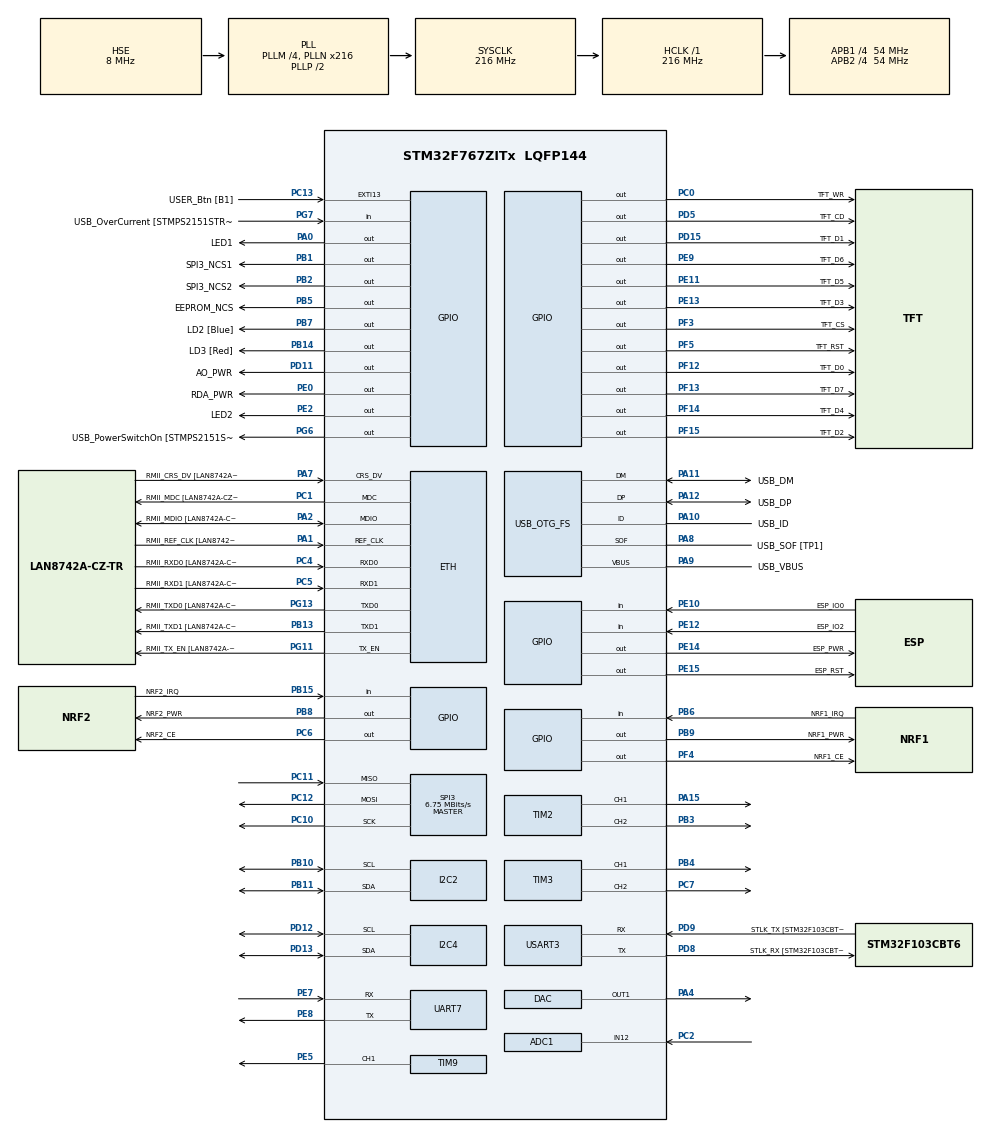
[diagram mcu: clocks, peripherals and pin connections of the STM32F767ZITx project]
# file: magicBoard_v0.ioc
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ADC1.Channel-0\#ChannelRegularConversion=ADC_CHANNEL_12
ADC1.Channel-1\#ChannelRegularConversion=ADC_CHANNEL_TEMPSENSOR
ADC1.DMAContinuousRequests=ENABLE
ADC1.ExternalTrigConv=ADC_EXTERNALTRIGCONV_T4_TRGO
ADC1.NbrOfConversion=2
ADC1.NbrOfConversionFlag=1
ADC1.Rank-0\#ChannelRegularConversion=1
ADC1.Rank-1\#ChannelRegularConversion=2
ADC1.SamplingTime-0\#ChannelRegularConversion=ADC_SAMPLETIME_480CYCLES
ADC1.SamplingTime-1\#ChannelRegularConversion=ADC_SAMPLETIME_480CYCLES
ADC1.master=1
Dma.ADC1.1.Direction=DMA_PERIPH_TO_MEMORY
Dma.ADC1.1.FIFOMode=DMA_FIFOMODE_DISABLE
Dma.ADC1.1.Instance=DMA2_Stream0
Dma.ADC1.1.MemDataAlignment=DMA_MDATAALIGN_WORD
Dma.ADC1.1.MemInc=DMA_MINC_ENABLE
Dma.ADC1.1.Mode=DMA_CIRCULAR
Dma.ADC1.1.PeriphDataAlignment=DMA_PDATAALIGN_WORD
Dma.ADC1.1.PeriphInc=DMA_PINC_DISABLE
Dma.ADC1.1.Priority=DMA_PRIORITY_LOW
Dma.Request0=UART7_RX
Dma.Request1=ADC1
Dma.Request2=USART3_RX
Dma.UART7_RX.0.Direction=DMA_PERIPH_TO_MEMORY
Dma.UART7_RX.0.FIFOMode=DMA_FIFOMODE_DISABLE
Dma.UART7_RX.0.Instance=DMA1_Stream3
Dma.UART7_RX.0.MemDataAlignment=DMA_MDATAALIGN_BYTE
Dma.UART7_RX.0.MemInc=DMA_MINC_ENABLE
Dma.UART7_RX.0.Mode=DMA_CIRCULAR
Dma.UART7_RX.0.PeriphDataAlignment=DMA_PDATAALIGN_BYTE
Dma.UART7_RX.0.PeriphInc=DMA_PINC_DISABLE
Dma.UART7_RX.0.Priority=DMA_PRIORITY_LOW
Dma.USART3_RX.2.Direction=DMA_PERIPH_TO_MEMORY
Dma.USART3_RX.2.FIFOMode=DMA_FIFOMODE_DISABLE
Dma.USART3_RX.2.Instance=DMA1_Stream1
Dma.USART3_RX.2.MemDataAlignment=DMA_MDATAALIGN_BYTE
Dma.USART3_RX.2.MemInc=DMA_MINC_ENABLE
Dma.USART3_RX.2.Mode=DMA_CIRCULAR
Dma.USART3_RX.2.PeriphDataAlignment=DMA_PDATAALIGN_BYTE
Dma.USART3_RX.2.PeriphInc=DMA_PINC_DISABLE
Dma.USART3_RX.2.Priority=DMA_PRIORITY_LOW
ETH.MediaInterface=HAL_ETH_RMII_MODE
FREERTOS.Queues01=wirelessData,16,uint16_t,0,Dynamic,NULL,NULL;wifiData,16,uint16_t,0,Dynamic,NULL,NULL
FREERTOS.Tasks01=defaultTask,24,128,StartDefaultTask,Default,NULL,Dynamic,NULL,NULL;nrfCOM,40,512,Start_nrfCOM,Default,NULL,Dynamic,NULL,NULL;displayTask,8,512,Start_displayTask,Default,NULL,Dynamic,NULL,NULL;uartCLI,8,128,Start_uartCLI,Default,NULL,Dynamic,NULL,NULL;WIFITask,24,128,StartWIFITask,Default,NULL,Dynamic,NULL,NULL
FREERTOS.configUSE_NEWLIB_REENTRANT=1
I2C2.Timing=0x20404768
I2C4.Timing=0x20404768
Mcu.Family=STM32F7
Mcu.Name=STM32F767ZITx
Mcu.Package=LQFP144
NVIC.DMA1_Stream1_IRQn=true\:5\:0\:false\:false\:true\:true\:false\:true\:true
NVIC.DMA1_Stream3_IRQn=true\:5\:0\:false\:false\:true\:true\:false\:true\:true
NVIC.DMA2_Stream0_IRQn=true\:5\:0\:false\:false\:true\:true\:false\:true\:true
NVIC.PriorityGroup=NVIC_PRIORITYGROUP_4
NVIC.RCC_IRQn=true\:5\:0\:false\:false\:true\:true\:true\:false\:true
NVIC.TIM8_TRG_COM_TIM14_IRQn=true\:15\:0\:false\:false\:true\:false\:false\:true\:true
NVIC.TimeBase=TIM8_TRG_COM_TIM14_IRQn
NVIC.TimeBaseIP=TIM14
NVIC.UART7_IRQn=true\:5\:0\:false\:false\:true\:true\:true\:true\:true
PA0/WKUP.GPIO_Label=LED1
PA0/WKUP.Signal=GPIO_Output
PA1.GPIO_Label=RMII_REF_CLK [LAN8742A-CZ-TR_REFCLK0]
PA1.Mode=RMII
PA1.Signal=ETH_REF_CLK
PA10.GPIO_Label=USB_ID
PA10.Mode=OTG/Dual_Role_Device
PA10.Signal=USB_OTG_FS_ID
PA11.GPIO_Label=USB_DM
PA11.Mode=OTG/Dual_Role_Device
PA11.Signal=USB_OTG_FS_DM
PA12.GPIO_Label=USB_DP
PA12.Mode=OTG/Dual_Role_Device
PA12.Signal=USB_OTG_FS_DP
PA13.GPIO_Label=TMS
PA13.Mode=Serial_Wire
PA13.Signal=SYS_JTMS-SWDIO
PA14.GPIO_Label=TCK
PA14.Mode=Serial_Wire
PA14.Signal=SYS_JTCK-SWCLK
PA15.Signal=S_TIM2_CH1_ETR
PA2.GPIO_Label=RMII_MDIO [LAN8742A-CZ-TR_MDIO]
PA2.Mode=RMII
PA2.Signal=ETH_MDIO
PA4.Signal=COMP_DAC1_group
PA7.GPIO_Label=RMII_CRS_DV [LAN8742A-CZ-TR_CRS_DV]
PA7.Mode=RMII
PA7.Signal=ETH_CRS_DV
PA8.GPIO_Label=USB_SOF [TP1]
PA8.Mode=Activate_SOF_FS
PA8.Signal=USB_OTG_FS_SOF
PA9.GPIO_Label=USB_VBUS
PA9.Mode=Activate_VBUS
PA9.Signal=USB_OTG_FS_VBUS
PB1.GPIO_Label=SPI3_NCS1
PB1.GPIO_Speed=GPIO_SPEED_FREQ_LOW
PB1.PinState=GPIO_PIN_SET
PB1.Signal=GPIO_Output
PB10.Mode=I2C
PB10.Signal=I2C2_SCL
PB11.Mode=I2C
PB11.Signal=I2C2_SDA
PB13.GPIO_Label=RMII_TXD1 [LAN8742A-CZ-TR_TXD1]
PB13.Mode=RMII
PB13.Signal=ETH_TXD1
PB14.GPIO_Label=LD3 [Red]
PB14.Signal=GPIO_Output
PB15.GPIO_Label=NRF2_IRQ
PB15.Signal=GPIO_Input
PB2.GPIO_Label=SPI3_NCS2
PB2.PinState=GPIO_PIN_SET
PB2.Signal=GPIO_Output
PB3.Signal=S_TIM2_CH2
PB4.Signal=S_TIM3_CH1
PB5.GPIO_Label=EEPROM_NCS
PB5.PinState=GPIO_PIN_SET
PB5.Signal=GPIO_Output
PB6.GPIO_Label=NRF1_IRQ
PB6.Signal=GPIO_Input
PB7.GPIO_Label=LD2 [Blue]
PB7.Signal=GPIO_Output
PB8.GPIO_Label=NRF2_PWR
PB8.PinState=GPIO_PIN_SET
PB8.Signal=GPIO_Output
PB9.GPIO_Label=NRF1_PWR
PB9.PinState=GPIO_PIN_SET
PB9.Signal=GPIO_Output
PC0.GPIO_Label=TFT_WR
PC0.Signal=GPIO_Output
PC1.GPIO_Label=RMII_MDC [LAN8742A-CZ-TR_MDC]
PC1.Mode=RMII
PC1.Signal=ETH_MDC
PC10.Mode=Full_Duplex_Master
PC10.Signal=SPI3_SCK
PC11.Mode=Full_Duplex_Master
PC11.Signal=SPI3_MISO
PC12.Mode=Full_Duplex_Master
PC12.Signal=SPI3_MOSI
PC13.GPIO_Label=USER_Btn [B1]
PC13.Signal=GPXTI13
PC14/OSC32_IN.Mode=LSE-External-Oscillator
PC14/OSC32_IN.Signal=RCC_OSC32_IN
PC15/OSC32_OUT.Mode=LSE-External-Oscillator
PC15/OSC32_OUT.Signal=RCC_OSC32_OUT
PC2.Signal=ADCx_IN12
PC4.GPIO_Label=RMII_RXD0 [LAN8742A-CZ-TR_RXD0]
PC4.Mode=RMII
PC4.Signal=ETH_RXD0
PC5.GPIO_Label=RMII_RXD1 [LAN8742A-CZ-TR_RXD1]
PC5.Mode=RMII
PC5.Signal=ETH_RXD1
PC6.GPIO_Label=NRF2_CE
PC6.Signal=GPIO_Output
PC7.Signal=S_TIM3_CH2
PD11.GPIO_Label=AO_PWR
PD11.PinState=GPIO_PIN_RESET
PD11.Signal=GPIO_Output
PD12.Mode=I2C
PD12.Signal=I2C4_SCL
PD13.Mode=I2C
PD13.Signal=I2C4_SDA
PD15.GPIO_Label=TFT_D1
PD15.Signal=GPIO_Output
PD5.GPIO_Label=TFT_CD
PD5.Signal=GPIO_Output
PD8.GPIO_Label=STLK_RX [STM32F103CBT6_PA3]
PD8.Mode=Asynchronous
PD8.Signal=USART3_TX
PD9.GPIO_Label=STLK_TX [STM32F103CBT6_PA2]
PD9.Mode=Asynchronous
PD9.Signal=USART3_RX
PE0.GPIO_Label=RDA_PWR
PE0.Signal=GPIO_Output
PE10.GPIO_Label=ESP_IO0
PE10.GPIO_PuPd=GPIO_NOPULL
PE10.Signal=GPIO_Input
PE11.GPIO_Label=TFT_D5
PE11.Signal=GPIO_Output
PE12.GPIO_Label=ESP_IO2
PE12.GPIO_PuPd=GPIO_NOPULL
PE12.Signal=GPIO_Input
PE13.GPIO_Label=TFT_D3
PE13.Signal=GPIO_Output
PE14.GPIO_Label=ESP_PWR
PE14.PinState=GPIO_PIN_SET
PE14.Signal=GPIO_Output
PE15.GPIO_Label=ESP_RST
PE15.Signal=GPIO_Output
PE2.GPIO_Label=LED2
PE2.Signal=GPIO_Output
PE5.Signal=S_TIM9_CH1
PE7.Mode=Asynchronous
PE7.Signal=UART7_RX
PE8.Mode=Asynchronous
PE8.Signal=UART7_TX
PE9.GPIO_Label=TFT_D6
PE9.Signal=GPIO_Output
PF12.GPIO_Label=TFT_D0
PF12.Signal=GPIO_Output
PF13.GPIO_Label=TFT_D7
PF13.Signal=GPIO_Output
PF14.GPIO_Label=TFT_D4
PF14.Signal=GPIO_Output
PF15.GPIO_Label=TFT_D2
PF15.Signal=GPIO_Output
PF3.GPIO_Label=TFT_CS
PF3.Signal=GPIO_Output
PF4.GPIO_Label=NRF1_CE
PF4.Signal=GPIO_Output
PF5.GPIO_Label=TFT_RST
PF5.Signal=GPIO_Output
PG11.GPIO_Label=RMII_TX_EN [LAN8742A-CZ-TR_TXEN]
PG11.Mode=RMII
PG11.Signal=ETH_TX_EN
PG13.GPIO_Label=RMII_TXD0 [LAN8742A-CZ-TR_TXD0]
PG13.Mode=RMII
PG13.Signal=ETH_TXD0
PG6.GPIO_Label=USB_PowerSwitchOn [STMPS2151STR_EN]
PG6.Signal=GPIO_Output
PG7.GPIO_Label=USB_OverCurrent [STMPS2151STR_FAULT]
PG7.Signal=GPIO_Input
PH0/OSC_IN.GPIO_Label=MCO [STM32F103CBT6_PA8]
PH0/OSC_IN.Mode=HSE-External-Clock-Source
PH0/OSC_IN.Signal=RCC_OSC_IN
PH1/OSC_OUT.Mode=HSE-External-Clock-Source
PH1/OSC_OUT.Signal=RCC_OSC_OUT
ProjectManager.HeapSize=0x200
ProjectManager.StackSize=0x400
ProjectManager.TargetToolchain=STM32CubeIDE
RCC.48MHZClocksFreq_Value=24000000
RCC.AHBFreq_Value=216000000
RCC.APB1CLKDivider=RCC_HCLK_DIV4
RCC.APB1Freq_Value=54000000
RCC.APB1TimFreq_Value=216000000
RCC.APB2CLKDivider=RCC_HCLK_DIV4
RCC.APB2Freq_Value=54000000
RCC.APB2TimFreq_Value=216000000
RCC.CortexFreq_Value=216000000
RCC.HCLKFreq_Value=216000000
RCC.HSE_VALUE=8000000
RCC.HSI_VALUE=16000000
RCC.PLLM=4
RCC.PLLMUL=RCC_PLL_MUL9
RCC.PLLN=216
RCC.PLLQ=9
RCC.PRESCALERUSB=RCC_USBCLKSOURCE_PLL_DIV1_5
RCC.RCC_TIM_PRescaler_Selection=RCC_TIMPRES_ACTIVATED
RCC.RTCClockSelection=RCC_RTCCLKSOURCE_LSE
RCC.SYSCLKFreq_VALUE=216000000
RCC.SYSCLKSource=RCC_SYSCLKSOURCE_PLLCLK
RCC.SYSCLKSourceVirtual=RCC_SYSCLKSOURCE_PLLCLK
RCC.USBFreq_Value=48000000
RCC.VCOOutputFreq_Value=432000000
SH.ADCx_IN12.0=ADC1_IN12,IN12
SH.COMP_DAC1_group.0=DAC_OUT1,DAC_OUT1
SH.S_TIM2_CH1_ETR.0=TIM2_CH1,PWM Generation1 CH1
SH.S_TIM2_CH2.0=TIM2_CH2,PWM Generation2 CH2
SH.S_TIM3_CH1.0=TIM3_CH1,PWM Generation1 CH1
SH.S_TIM3_CH2.0=TIM3_CH2,PWM Generation2 CH2
SH.S_TIM9_CH1.0=TIM9_CH1,PWM Generation1 CH1
SPI3.BaudRatePrescaler=SPI_BAUDRATEPRESCALER_8
SPI3.CalculateBaudRate=6.75 MBits/s
SPI3.DataSize=SPI_DATASIZE_8BIT
SPI3.Direction=SPI_DIRECTION_2LINES
SPI3.Mode=SPI_MODE_MASTER
SPI3.VirtualType=VM_MASTER
TIM2.Channel-PWM\ Generation1\ CH1=TIM_CHANNEL_1
TIM2.Channel-PWM\ Generation2\ CH2=TIM_CHANNEL_2
TIM3.Channel-PWM\ Generation1\ CH1=TIM_CHANNEL_1
TIM3.Channel-PWM\ Generation2\ CH2=TIM_CHANNEL_2
TIM4.Channel-Output\ Compare1\ No\ Output=TIM_CHANNEL_1
TIM4.Period=9999
TIM4.Prescaler=1080
TIM4.TIM_MasterOutputTrigger=TIM_TRGO_UPDATE
TIM9.Channel-PWM\ Generation1\ CH1=TIM_CHANNEL_1
USART3.VirtualMode-Asynchronous=VM_ASYNC
VP_ADC1_TempSens_Input.Mode=IN-TempSens
VP_FREERTOS_VS_CMSIS_V2.Mode=CMSIS_V2
VP_RTC_VS_RTC_Activate.Mode=RTC_Enabled
VP_RTC_VS_RTC_Calendar.Mode=RTC_Calendar
VP_SYS_VS_tim14.Mode=TIM14
VP_TIM2_VS_ClockSourceINT.Mode=Internal
VP_TIM3_VS_ClockSourceINT.Mode=Internal
VP_TIM4_VS_ClockSourceINT.Mode=Internal
VP_TIM4_VS_no_output1.Mode=Output Compare1 No Output
VP_TIM9_VS_ClockSourceINT.Mode=Internal
board=NUCLEO-F767ZI

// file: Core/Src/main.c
/* USER CODE BEGIN Header */
/**
  ******************************************************************************
  * @file           : main.c
  * @brief          : Main program body
  ******************************************************************************
  * @attention
  *
  * Copyright (c) 2022 STMicroelectronics.
  * All rights reserved.
  *
  * This software is licensed under terms that can be found in the LICENSE file
  * in the root directory of this software component.
  * If no LICENSE file comes with this software, it is provided AS-IS.
  *
  ******************************************************************************
  */
/* USER CODE END Header */
#include "main.h"
#include "cmsis_os.h"
#include "adc.h"
#include "dac.h"
#include "dma.h"
#include "eth.h"
#include "i2c.h"
#include "rtc.h"
#include "spi.h"
#include "tim.h"
#include "usart.h"
#include "usb_otg.h"
#include "gpio.h"

/* USER CODE BEGIN Includes */
#include <stdio.h>

#include "nrf24l01p_driver.h"
#include "nrf24l01p_driver_B.h"

#include "esp8266_http_server.h"

#include "nvm_app.h"

#include "rda5807m.h"

#include "tft.h"
#include "fonts.h"
#include "functions.h"

#include "cli.h"

#include "cmd_dispatcher.h"

#include "print_magneto.h"
#include "calibri16.h"
/* USER CODE END Includes */

/* USER CODE BEGIN PD */
#define WIFI_DEMO 0
#define TFT_DEMO 0
#define NRF_DEMO 0
#define EEPROM_DEMO 1
#define FM_RADIO_DEMO 0
#define INT_ADC_DEMO 0
#define DEMO_ENDLESS_LOOP 0
/* USER CODE END PD */

void SystemClock_Config(void);
void PeriphCommonClock_Config(void);
void MX_FREERTOS_Init(void);

int main(void)
{
  /* USER CODE BEGIN 1 */

	/* User input structure*/
	cli_t cli = {0};
#if TFT_DEMO
  uint32_t tft_Cursor = 5;
  uint32_t tft_Line = 300;
  char tft_TestStr[]= "I am a demo application for the magiBoard!";
  RTC_TimeTypeDef tft_Time = {0};
#endif

#if NRF_DEMO
  uint8_t nrf_lng1 = 0;
  uint8_t nrf_lng2 = 0;
  uint8_t nrf1_tx[33] = {0};
  uint8_t nrf1_rx[33] = {0};
  uint8_t nrf2_tx[33] = {0};
  uint8_t nrf2_rx[33] = {0};
#endif
  /* USER CODE END 1 */

  /* MCU Configuration--------------------------------------------------------*/

  /* Reset of all peripherals, Initializes the Flash interface and the Systick. */
  HAL_Init();

  /* Configure the system clock */
  SystemClock_Config();

/* Configure the peripherals common clocks */
  PeriphCommonClock_Config();

  /* Initialize all configured peripherals */
  MX_GPIO_Init();
  MX_DMA_Init();
  MX_USART3_UART_Init();
  MX_USB_OTG_FS_USB_Init();
  MX_DAC_Init();
  MX_SPI3_Init();
  MX_TIM3_Init();
  MX_ETH_Init();
  MX_UART7_Init();
  MX_TIM2_Init();
  MX_I2C2_Init();
  MX_I2C4_Init();
  MX_ADC1_Init();
  MX_TIM9_Init();
  MX_RTC_Init();
  MX_TIM4_Init();
  /* USER CODE BEGIN 2 */

  /* Initiliaze UART-console input */
  cli_init();

  /* Initiliaze LCD */
  reset();
  tft_init(readID());
  fillScreen(BLACK);
  HAL_GPIO_WritePin(LED1_GPIO_Port, LED1_Pin, GPIO_PIN_SET);

#if INT_ADC_DEMO
  //measurements_open();
#endif
#if TFT_DEMO
  /* TFT functionality overview*/

  reset();
  tft_init(readID());
  fillScreen(BLACK);

  /* Print a size-16 string - general usage*/
  for(uint32_t i = 0; i < strlen(tft_TestStr); i++)
  {
	  tft_Cursor += sPrintCalibri16(tft_Cursor, tft_Line, tft_TestStr[i] - ASCII_OFFSET, WHITE);
  }

  /* Get time */
  HAL_RTC_GetTime(&hrtc, &tft_Time, RTC_FORMAT_BIN);

  /* Print a size-100 numbers - current time usage*/
  printMagneto100(MAGNETO_100_POS_0, MAGNETO_100_LINE, tft_Time.Hours/10);
  printMagneto100(MAGNETO_100_POS_1, MAGNETO_100_LINE, tft_Time.Hours%10);
  printMagnetoComa();
  printMagneto100(MAGNETO_100_POS_2, MAGNETO_100_LINE, tft_Time.Minutes/10);
  printMagneto100(MAGNETO_100_POS_3, MAGNETO_100_LINE, tft_Time.Minutes%10);

  /* Print a size-40 text - informal usage (temperature)*/
  tft_Cursor = MAGNETO_40_START;
  tft_Cursor += printMagneto40(tft_Cursor, MAGNETO_40_LINE_0, '1' - ASCII_OFFSET);
  tft_Cursor += printMagneto40(tft_Cursor, MAGNETO_40_LINE_0, '1' - ASCII_OFFSET);
  tft_Cursor += printMagneto40(tft_Cursor, MAGNETO_40_LINE_0, '.' - ASCII_OFFSET);
  tft_Cursor += printMagneto40(tft_Cursor, MAGNETO_40_LINE_0, '1' - ASCII_OFFSET);
  tft_Cursor += printMagneto40Degree(tft_Cursor, MAGNETO_40_LINE_0);
  tft_Cursor += printMagneto40(tft_Cursor, MAGNETO_40_LINE_0, 'C' - ASCII_OFFSET);
#endif

#if EEPROM_DEMO
  /* Read - out some NVM EEPROM stored custom data */
  DEBUG_PRINT("AudioOut %d\r\n", NVM_GetAudioOutEnable());
  DEBUG_PRINT("ESP %d\r\n", NVM_GetESPEnable());
  DEBUG_PRINT("RDA %d\r\n", NVM_GetRDAEnable());
  DEBUG_PRINT("RDAfrequency %d\r\n", NVM_GetRDAfrequency());
  DEBUG_PRINT("RDAvolume %d\r\n", NVM_GetRDAvolume());

  RTC_TimeTypeDef time = {0};
  RTC_DateTypeDef date = {0};

  HAL_RTC_SetDate(&hrtc, &date, RTC_FORMAT_BIN);
  HAL_RTC_SetTime(&hrtc, &time, RTC_FORMAT_BIN);

#endif

#if WIFI_DEMO
  /* ESP8226-01 Initialization */
  ESP_HTTPinit();
#endif

#if FM_RADIO_DEMO
  /* Initialize RDA5807M */
  RDA5807mPowerOn();
  RDA5807mInit(9170, 1);
  RDA5807mMute(0);
  /* Enable AUDIO_OUT amplifier */
  HAL_GPIO_WritePin(AO_PWR_GPIO_Port, AO_PWR_Pin, GPIO_PIN_SET);
#endif

#if NRF_DEMO

  /* Initialization of both NRF module */
  NRF_powerDown();
  NRF_powerDown_B();
  HAL_Delay(500);
  NRF_powerUp();
  NRF_powerUp_B();
  HAL_Delay(500);

  DEBUG_PRINT("NRF1 STATUS: 0x%02lx\n", NRF_powerCycle(HAL_Delay));
  DEBUG_PRINT("NRF2 STATUS: 0x%02lx\n", NRF_powerCycle_B(HAL_Delay));

  NRF_configure(true);
  NRF_configure_B(false);
#endif
  while(DEMO_ENDLESS_LOOP)
  {
	  int32_t ch12 = 0, temp = 0;
	  //if(measurement_get(&ch12, &temp))
	  {
		  DEBUG_PRINT("ch12 %ld\ntemp %ld\r\n", ch12, temp);
	  }
	  /* Process console users UART input*/
	  cli = cli_process();
	  if(cli.pBegin != NULL &&
			  cli.length != 0 &&
			  cli.length != CLI_PROCESS_TIMEOUT)
	  {
		  CmdDispatch(cli.pBegin, cli.length);
	  }

	  /* Just toggle magicBoard's general purpose LEDS*/
	  HAL_GPIO_TogglePin(LED1_GPIO_Port, LED1_Pin);
	  HAL_GPIO_TogglePin(LED2_GPIO_Port, LED2_Pin);

#if NRF_DEMO

	  /* Generate some payload for both NRFs - use ARM's 1ms tick */
	  sprintf((char*)nrf1_tx, "%032ld", HAL_GetTick());
	  sprintf((char*)nrf2_tx, "%032ld", 0x7FFFFFFF - HAL_GetTick());

	  /* Shift payload in the NRFs*/
	  NRF_setW_TX_PAYLOAD(nrf1_tx, 32);
	  NRF_set_W_ACK_PAYLOAD_B(0, nrf2_tx, 32);

	  /* Start receive, start transmit */
	  NRF_CEactivate_B();
	  NRF_CEactivate();

	  /* Wait long enought for reception and ACK */
	  HAL_Delay(5);

	  /* Deactivate reception and transmission */
	  NRF_CEdeactivate_B();
	  NRF_CEdeactivate();

	  /* Check whether IRQ fired (receive, transmit or error occured)*/
	  if(NRF_getIRQ())
	  {
		  DEBUG_PRINT("NRF1 IRQ\n");
		  HAL_Delay(50);
	  }

	  if(NRF_getIRQ_B())
	  {
		  DEBUG_PRINT("NRF2 IRQ\n");
		  HAL_Delay(50);
	  }

	  /* Check receive and transmit states, get potential payload and payload length*/
	  nrf_lng1 = NRF_postProcess(0, nrf1_rx);
	  nrf_lng2 = NRF_postProcess_B(0, nrf2_rx);

	  /* Print payloads when available */
	  if(nrf_lng1 && nrf_lng1 != (uint8_t)(-1))
	  {
		  DEBUG_PRINT("%s\n", nrf1_rx);
		  HAL_Delay(50);
	  }
	  if(nrf_lng2 && nrf_lng2 != (uint8_t)(-1))
	  {
		  DEBUG_PRINT("%s\n", nrf2_rx);
	  }
#endif
	  HAL_Delay(100);
  }

  /* USER CODE END 2 */

  /* Init scheduler */
  osKernelInitialize();  /* Call init function for freertos objects (in freertos.c) */
  MX_FREERTOS_Init();

  /* Start scheduler */
  osKernelStart();

  /* We should never get here as control is now taken by the scheduler */
  /* Infinite loop */
  while (1)
  {

  }
}

void SystemClock_Config(void)
{
  RCC_OscInitTypeDef RCC_OscInitStruct = {0};
  RCC_ClkInitTypeDef RCC_ClkInitStruct = {0};

  /** Configure LSE Drive Capability
  */
  HAL_PWR_EnableBkUpAccess();
  __HAL_RCC_LSEDRIVE_CONFIG(RCC_LSEDRIVE_LOW);

  /** Configure the main internal regulator output voltage
  */
  __HAL_RCC_PWR_CLK_ENABLE();
  __HAL_PWR_VOLTAGESCALING_CONFIG(PWR_REGULATOR_VOLTAGE_SCALE1);

  /** Initializes the RCC Oscillators according to the specified parameters
  * in the RCC_OscInitTypeDef structure.
  */
  RCC_OscInitStruct.OscillatorType = RCC_OSCILLATORTYPE_HSE|RCC_OSCILLATORTYPE_LSE;
  RCC_OscInitStruct.HSEState = RCC_HSE_BYPASS;
  RCC_OscInitStruct.LSEState = RCC_LSE_ON;
  RCC_OscInitStruct.PLL.PLLState = RCC_PLL_ON;
  RCC_OscInitStruct.PLL.PLLSource = RCC_PLLSOURCE_HSE;
  RCC_OscInitStruct.PLL.PLLM = 4;
  RCC_OscInitStruct.PLL.PLLN = 216;
  RCC_OscInitStruct.PLL.PLLP = RCC_PLLP_DIV2;
  RCC_OscInitStruct.PLL.PLLQ = 9;
  RCC_OscInitStruct.PLL.PLLR = 2;
  if (HAL_RCC_OscConfig(&RCC_OscInitStruct) != HAL_OK)
  {
    Error_Handler();
  }

  /** Activate the Over-Drive mode
  */
  if (HAL_PWREx_EnableOverDrive() != HAL_OK)
  {
    Error_Handler();
  }

  /** Initializes the CPU, AHB and APB buses clocks
  */
  RCC_ClkInitStruct.ClockType = RCC_CLOCKTYPE_HCLK|RCC_CLOCKTYPE_SYSCLK
                              |RCC_CLOCKTYPE_PCLK1|RCC_CLOCKTYPE_PCLK2;
  RCC_ClkInitStruct.SYSCLKSource = RCC_SYSCLKSOURCE_PLLCLK;
  RCC_ClkInitStruct.AHBCLKDivider = RCC_SYSCLK_DIV1;
  RCC_ClkInitStruct.APB1CLKDivider = RCC_HCLK_DIV4;
  RCC_ClkInitStruct.APB2CLKDivider = RCC_HCLK_DIV4;

  if (HAL_RCC_ClockConfig(&RCC_ClkInitStruct, FLASH_LATENCY_7) != HAL_OK)
  {
    Error_Handler();
  }
}

void PeriphCommonClock_Config(void)
{
  RCC_PeriphCLKInitTypeDef PeriphClkInitStruct = {0};

  /** Initializes the peripherals clock
  */
  PeriphClkInitStruct.PeriphClockSelection = RCC_PERIPHCLK_TIM;
  PeriphClkInitStruct.TIMPresSelection = RCC_TIMPRES_ACTIVATED;

  if (HAL_RCCEx_PeriphCLKConfig(&PeriphClkInitStruct) != HAL_OK)
  {
    Error_Handler();
  }
}

void HAL_TIM_PeriodElapsedCallback(TIM_HandleTypeDef *htim)
{
  if (htim->Instance == TIM14) {
    HAL_IncTick();
  }
}

void Error_Handler(void)
{
  __disable_irq();
  while (1)
  {
  }
}

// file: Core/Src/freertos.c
/* USER CODE BEGIN Header */
/**
  ******************************************************************************
  * File Name          : freertos.c
  * Description        : Code for freertos applications
  ******************************************************************************
  * @attention
  *
  * Copyright (c) 2023 STMicroelectronics.
  * All rights reserved.
  *
  * This software is licensed under terms that can be found in the LICENSE file
  * in the root directory of this software component.
  * If no LICENSE file comes with this software, it is provided AS-IS.
  *
  ******************************************************************************
  */
/* USER CODE END Header */

#include "FreeRTOS.h"
#include "task.h"
#include "main.h"
#include "cmsis_os.h"

/* USER CODE BEGIN Includes */
#include <stdbool.h>
#include <string.h>
#include <stdio.h>

#include "cli.h"
#include "nrf24l01p_defines.h"
#include "nrf24l01p_driver.h"

#include "tft.h"
#include "fonts.h"
#include "functions.h"
#include "print_magneto.h"
#include "calibri16.h"

#include "cli.h"

#include "rtc.h"
#include "nvm_app.h"
#include "esp8266_http_server.h"
/* USER CODE END Includes */

/* USER CODE BEGIN PTD */
typedef struct payload
{
	uint32_t vdda;
	uint32_t temp_ntc;
	uint32_t temp_sens;
}payload_t;
/* USER CODE END PTD */

/* USER CODE BEGIN PD */
typedef struct Measurement
{
	int32_t ntc2;
	int32_t ntc1;
	int32_t oagp;
	int32_t curr;
	int32_t tmpi;
	int32_t vdda;
	int32_t tmpe;
}Measurement_t;
/* USER CODE END PD */

/* Definitions for defaultTask */
osThreadId_t defaultTaskHandle;
const osThreadAttr_t defaultTask_attributes = {
  .name = "defaultTask",
  .stack_size = 128 * 4,
  .priority = (osPriority_t) osPriorityNormal,
};
/* Definitions for nrfCOM */
osThreadId_t nrfCOMHandle;
const osThreadAttr_t nrfCOM_attributes = {
  .name = "nrfCOM",
  .stack_size = 512 * 4,
  .priority = (osPriority_t) osPriorityHigh,
};
/* Definitions for displayTask */
osThreadId_t displayTaskHandle;
const osThreadAttr_t displayTask_attributes = {
  .name = "displayTask",
  .stack_size = 512 * 4,
  .priority = (osPriority_t) osPriorityLow,
};
/* Definitions for uartCLI */
osThreadId_t uartCLIHandle;
const osThreadAttr_t uartCLI_attributes = {
  .name = "uartCLI",
  .stack_size = 128 * 4,
  .priority = (osPriority_t) osPriorityLow,
};
/* Definitions for WIFITask */
osThreadId_t WIFITaskHandle;
const osThreadAttr_t WIFITask_attributes = {
  .name = "WIFITask",
  .stack_size = 128 * 4,
  .priority = (osPriority_t) osPriorityNormal,
};

/* USER CODE BEGIN FunctionPrototypes */
/* Definitions for wirelessData */
osMessageQueueId_t wirelessDataHandle;
const osMessageQueueAttr_t wirelessData_attributes = {
  .name = "wirelessData"
};
osMessageQueueId_t wifiDataHandle;
const osMessageQueueAttr_t wifiData_attributes = {
  .name = "wifiData"
};
/* USER CODE END FunctionPrototypes */

void StartDefaultTask(void *argument);
void Start_nrfCOM(void *argument);
void Start_displayTask(void *argument);
void Start_uartCLI(void *argument);
void StartWIFITask(void *argument);

void MX_FREERTOS_Init(void); /* (MISRA C 2004 rule 8.1) */

void MX_FREERTOS_Init(void) {

  /* Create the queue(s) */
  /* creation of wirelessData */
  wirelessDataHandle = osMessageQueueNew (16, sizeof(uint16_t), &wirelessData_attributes);

  /* creation of wifiData */
  wifiDataHandle = osMessageQueueNew (16, sizeof(uint16_t), &wifiData_attributes);

  /* USER CODE BEGIN RTOS_QUEUES */
  /* add queues, ... */
  wirelessDataHandle = osMessageQueueNew (1, sizeof(Measurement_t), &wirelessData_attributes);
  wifiDataHandle = osMessageQueueNew (16, sizeof(uint16_t), &wifiData_attributes);
  /* USER CODE END RTOS_QUEUES */

  /* Create the thread(s) */
  /* creation of defaultTask */
  defaultTaskHandle = osThreadNew(StartDefaultTask, NULL, &defaultTask_attributes);

  /* creation of nrfCOM */
  nrfCOMHandle = osThreadNew(Start_nrfCOM, NULL, &nrfCOM_attributes);

  /* creation of displayTask */
  displayTaskHandle = osThreadNew(Start_displayTask, NULL, &displayTask_attributes);

  /* creation of uartCLI */
  uartCLIHandle = osThreadNew(Start_uartCLI, NULL, &uartCLI_attributes);

  /* creation of WIFITask */
  WIFITaskHandle = osThreadNew(StartWIFITask, NULL, &WIFITask_attributes);

}

void StartDefaultTask(void *argument)
{
  /* USER CODE BEGIN StartDefaultTask */
  /* Infinite loop */
  for(;;)
  {
    HAL_GPIO_WritePin(LED2_GPIO_Port, LED2_Pin, GPIO_PIN_SET);
    osDelay(50);
    HAL_GPIO_WritePin(LED2_GPIO_Port, LED2_Pin, GPIO_PIN_RESET);
    osDelay(950);
  }
  /* USER CODE END StartDefaultTask */
}

void Start_nrfCOM(void *argument)
{
  /* USER CODE BEGIN Start_nrfCOM */
	static Measurement_t payload = {0};
	bool synced = false;
	uint8_t status = 0;
  /* Infinite loop */
  for(;;)
  {
	  NRF_powerDown();
	  osDelay(105);
	  NRF_powerUp();
	  osDelay(105);

	  DEBUG_PRINT("NRF STATUS 1 attempt: 0x%02x\n", NRF_getSTATUS());

	  NRF_configure(false);

	  NRF_set_W_ACK_PAYLOAD(0, (uint8_t*)"DummyACK", strlen("DummyACK"));

	  for(;;)
	  {

		  NRF_CEactivate();
		  osDelay(200);
		  NRF_CEdeactivate();

		  status = NRF_getSTATUS();

		  if(status & (1 << RX_DR))
		  {
			  synced = true;
			  NRF_getR_RX_PAYLOAD((uint8_t*)&payload, sizeof(Measurement_t));

			  DEBUG_PRINT("NTC2 %ld\n", payload.ntc2);
			  DEBUG_PRINT("NTC1 %ld\n", payload.ntc1);
			  DEBUG_PRINT("OAGP %ld\n", payload.oagp);
			  DEBUG_PRINT("CURR %ld\n", payload.curr);
			  DEBUG_PRINT("TMPI %ld\n", payload.tmpi);
			  DEBUG_PRINT("VDDA %ld\n", payload.vdda);
			  DEBUG_PRINT("TMPE %ld\n", payload.tmpe);

			  NRF_setSTATUS(1 << RX_DR | 1 << TX_DS);

			  osMessageQueuePut(wirelessDataHandle, (uint8_t*)&payload, 0, 1);

			  NRF_set_W_ACK_PAYLOAD(0, (uint8_t*)"DummyACK", strlen("DummyACK"));

		  }
		  else
		  {
			  synced = false;
		  }
	  }
    osDelay(1);
  }
  /* USER CODE END Start_nrfCOM */
}

void Start_displayTask(void *argument)
{
  /* USER CODE BEGIN Start_displayTask */
	  RTC_TimeTypeDef previous = {0};
	  RTC_TimeTypeDef current = {0};
	  RTC_DateTypeDef dummy = {0};

	  previous.Hours = 11;
	  previous.Minutes = 11;
	  previous.Seconds = 11;
	  current.Hours = 0;
	  current.Minutes = 0;
	  current.Seconds = 0;

	  bool firstTime = true;
	  osStatus_t msg_state;
	  Measurement_t data;
	  int32_t prev_temp = 0;
	  uint32_t tft_Cursor;
	  char str_vdda[16];

	  printMagnetoComa();

	  NVM_GetHardcodeTime(&current);

  /* Infinite loop */
  for(;;)
  {
	  /* It's a STM HAL bug ... without the reading date
	   * the read time does not work */
	  HAL_RTC_GetDate(&hrtc, &dummy, RTC_FORMAT_BIN);
	  HAL_RTC_GetTime(&hrtc, &current, RTC_FORMAT_BIN);

	  if(memcmp(&current, &previous, sizeof(RTC_TimeTypeDef)) || firstTime)
	  {
		  firstTime = false;
		  /* Print a size-100 numbers - current time usage*/
		  if(previous.Hours/10 != current.Hours/10)
		  {
			  eraseMagneto100(MAGNETO_100_POS_0, MAGNETO_100_LINE, previous.Hours/10);
			  printMagneto100(MAGNETO_100_POS_0, MAGNETO_100_LINE, current.Hours/10);
		  }
		  if(previous.Hours%10 != current.Hours%10)
		  {
			  eraseMagneto100(MAGNETO_100_POS_1, MAGNETO_100_LINE, previous.Hours%10);
			  printMagneto100(MAGNETO_100_POS_1, MAGNETO_100_LINE, current.Hours%10);
		  }
		  if(previous.Minutes/10 != current.Minutes/10)
		  {
			  eraseMagneto100(MAGNETO_100_POS_2, MAGNETO_100_LINE, previous.Minutes/10);
			  printMagneto100(MAGNETO_100_POS_2, MAGNETO_100_LINE, current.Minutes/10);
		  }
		  if(previous.Minutes%10 != current.Minutes%10)
		  {
			  eraseMagneto100(MAGNETO_100_POS_3, MAGNETO_100_LINE, previous.Minutes%10);
			  printMagneto100(MAGNETO_100_POS_3, MAGNETO_100_LINE, current.Minutes%10);
		  }
		  memcpy(&previous, &current, sizeof(RTC_TimeTypeDef));
	  }

	  msg_state = osMessageQueueGet(wirelessDataHandle, (void*)&data, 0, 1);

	  if(msg_state == osOK && data.tmpe != INT32_MIN)
	  {

		  data.tmpe= data.tmpe / 100;

		  if(data.tmpe != prev_temp)
		  {

			  tft_Cursor = MAGNETO_40_START;
			  sprintf(str_vdda, "%ld.%ld", prev_temp/10, prev_temp%10);

			  for(uint32_t idx = 0; idx < strlen(str_vdda); idx++)
			  {
				 tft_Cursor += eraseMagneto40(tft_Cursor, MAGNETO_40_LINE_0, str_vdda[idx] - ASCII_OFFSET);
			  }

			  tft_Cursor += eraseMagneto40Degree(tft_Cursor, MAGNETO_40_LINE_0);
			  tft_Cursor += eraseMagneto40(tft_Cursor, MAGNETO_40_LINE_0, 'C' - ASCII_OFFSET);

			  tft_Cursor = MAGNETO_40_START;
			  sprintf(str_vdda, "%ld.%ld", data.tmpe/10, data.tmpe%10);

			  for(uint32_t idx = 0; idx < strlen(str_vdda); idx++)
			  {
				  tft_Cursor += printMagneto40(tft_Cursor, MAGNETO_40_LINE_0, str_vdda[idx] - ASCII_OFFSET);
			  }

			  tft_Cursor += printMagneto40Degree(tft_Cursor, MAGNETO_40_LINE_0);
			  tft_Cursor += printMagneto40(tft_Cursor, MAGNETO_40_LINE_0, 'C' - ASCII_OFFSET);

			  prev_temp = data.tmpe;
		  }
	  }

	  osDelay(1000);
  }
  /* USER CODE END Start_displayTask */
}

void Start_uartCLI(void *argument)
{
  /* USER CODE BEGIN Start_uartCLI */
  /* Infinite loop */
  for(;;)
  {
    osDelay(100);
  }
  /* USER CODE END Start_uartCLI */
}

void StartWIFITask(void *argument)
{
  /* USER CODE BEGIN StartWIFITask */

	char *pHTTPReq = NULL;
    uint32_t httpReqLng = 0;

    NVM_SetWifi(WIFI_ADR_0, (uint8_t*)"\"UPCEDFF983\",\"tb6mhkmxW6ee\"",
    		strlen("\"UPCEDFF983\",\"tb6mhkmxW6ee\""));

	ESP_HTTPinit();

  /* Infinite loop */
  for(;;)
  {
      if(ESP_RET_OK == ESP_CheckReceiveHTTP(&pHTTPReq, &httpReqLng))
      {
          ESP_ProcessHTTP(pHTTPReq, httpReqLng);
      }
    osDelay(100);
  }
  /* USER CODE END StartWIFITask */
}
